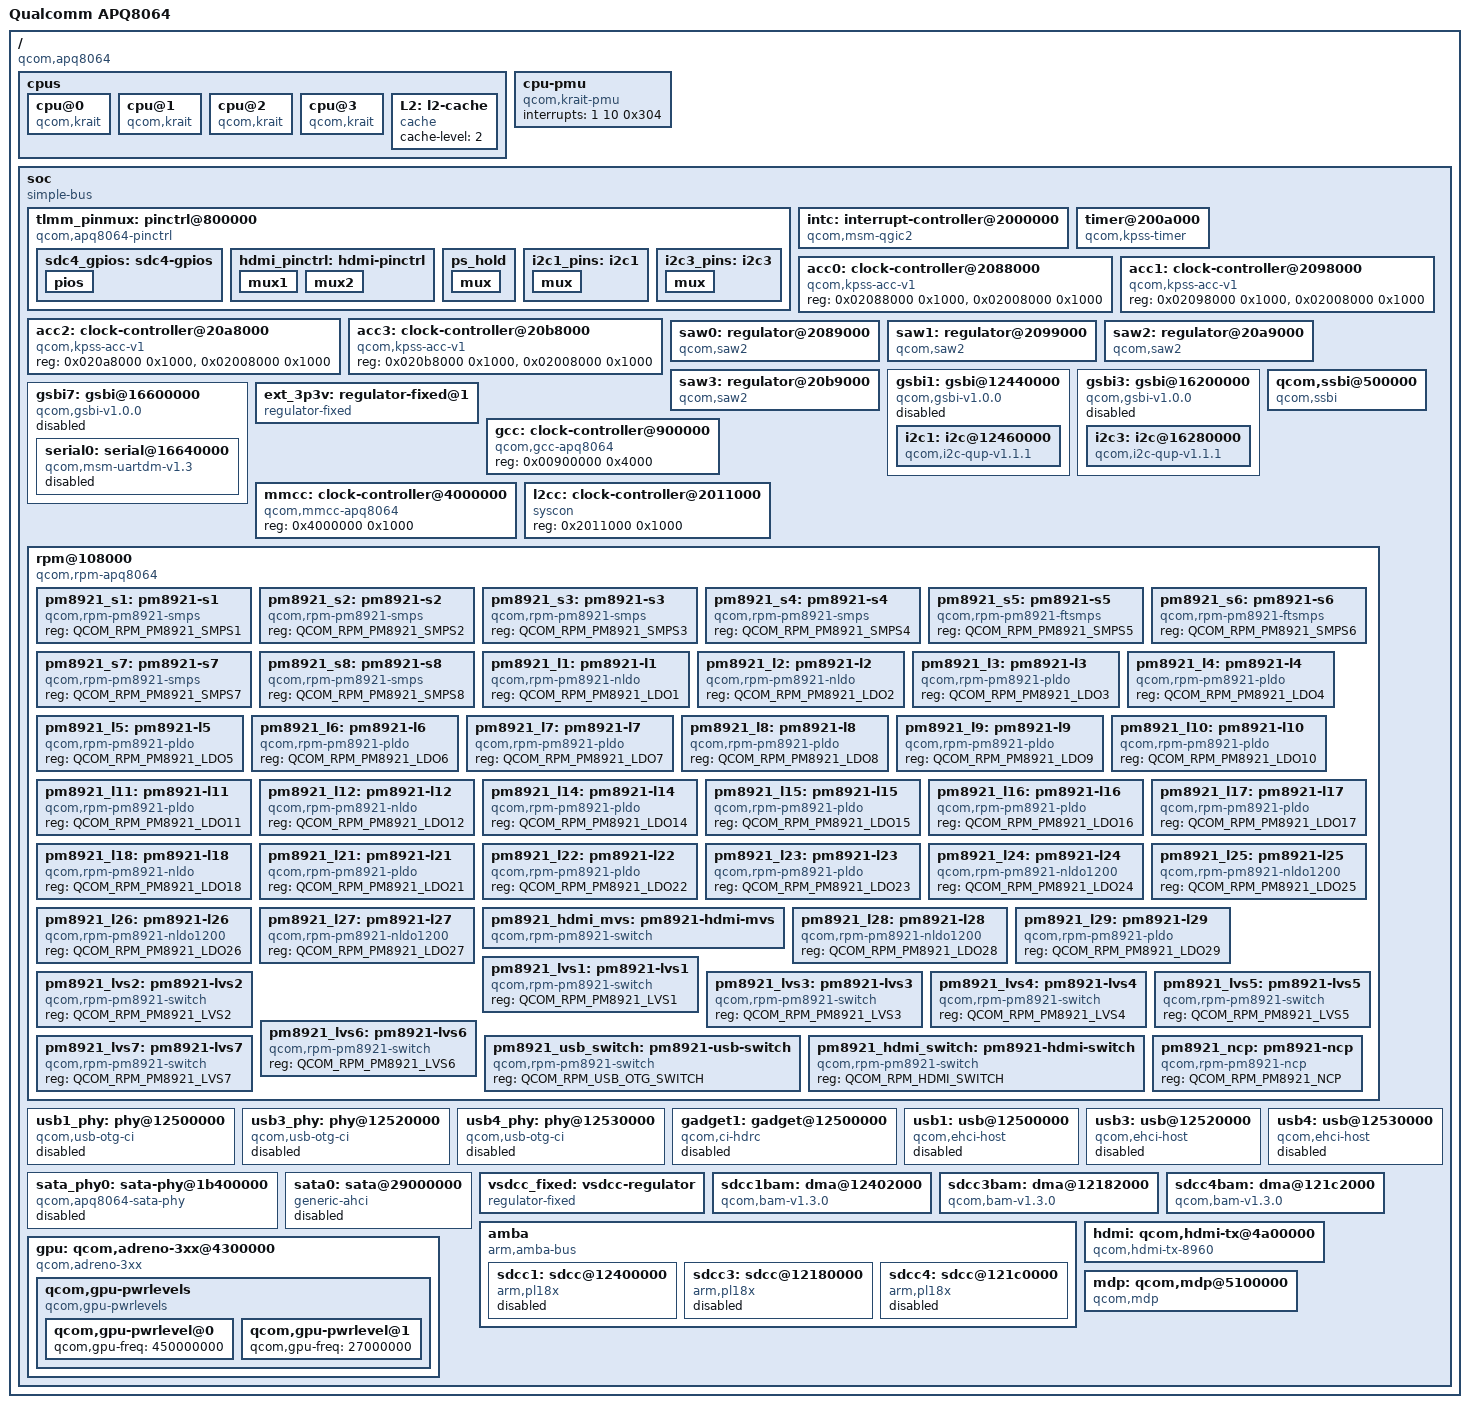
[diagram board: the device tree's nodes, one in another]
/dts-v1/;

#include "skeleton.dtsi"
#include <dt-bindings/gpio/gpio.h>
#include <dt-bindings/clock/qcom,gcc-msm8960.h>
#include <dt-bindings/reset/qcom,gcc-msm8960.h>
#include <dt-bindings/clock/qcom,mmcc-msm8960.h>
#include <dt-bindings/mfd/qcom-rpm.h>
#include <dt-bindings/soc/qcom,gsbi.h>
#include <dt-bindings/interrupt-controller/arm-gic.h>

/ {
	model = "Qualcomm APQ8064";
	compatible = "qcom,apq8064";
	interrupt-parent = <&intc>;

	cpus {
		#address-cells = <1>;
		#size-cells = <0>;

		cpu@0 {
			compatible = "qcom,krait";
			enable-method = "qcom,kpss-acc-v1";
			device_type = "cpu";
			reg = <0>;
			next-level-cache = <&L2>;
			qcom,acc = <&acc0>;
			qcom,saw = <&saw0>;
		};

		cpu@1 {
			compatible = "qcom,krait";
			enable-method = "qcom,kpss-acc-v1";
			device_type = "cpu";
			reg = <1>;
			next-level-cache = <&L2>;
			qcom,acc = <&acc1>;
			qcom,saw = <&saw1>;
		};

		cpu@2 {
			compatible = "qcom,krait";
			enable-method = "qcom,kpss-acc-v1";
			device_type = "cpu";
			reg = <2>;
			next-level-cache = <&L2>;
			qcom,acc = <&acc2>;
			qcom,saw = <&saw2>;
		};

		cpu@3 {
			compatible = "qcom,krait";
			enable-method = "qcom,kpss-acc-v1";
			device_type = "cpu";
			reg = <3>;
			next-level-cache = <&L2>;
			qcom,acc = <&acc3>;
			qcom,saw = <&saw3>;
		};

		L2: l2-cache {
			compatible = "cache";
			cache-level = <2>;
		};
	};

	cpu-pmu {
		compatible = "qcom,krait-pmu";
		interrupts = <1 10 0x304>;
	};

	soc: soc {
		#address-cells = <1>;
		#size-cells = <1>;
		ranges;
		compatible = "simple-bus";

		tlmm_pinmux: pinctrl@800000 {
			compatible = "qcom,apq8064-pinctrl";
			reg = <0x800000 0x4000>;

			gpio-controller;
			#gpio-cells = <2>;
			interrupt-controller;
			#interrupt-cells = <2>;
			interrupts = <0 16 IRQ_TYPE_LEVEL_HIGH>;

			pinctrl-names = "default";
			pinctrl-0 = <&ps_hold>;

			sdc4_gpios: sdc4-gpios {
				pios {
					pins = "gpio63", "gpio64", "gpio65", "gpio66", "gpio67", "gpio68";
					function = "sdc4";
				};
			};

			hdmi_pinctrl: hdmi-pinctrl {
				mux1 {
					pins = "gpio69", "gpio70", "gpio71";
					function = "hdmi";
					bias-pull-up;
					drive-strength = <2>;
				};
				mux2 {
					pins = "gpio72";
					function = "hdmi";
					bias-pull-down;
					drive-strength = <16>;
				};
			};
			ps_hold: ps_hold {
				mux {
					pins = "gpio78";
					function = "ps_hold";
				};
			};

			i2c1_pins: i2c1 {
				mux {
					pins = "gpio20", "gpio21";
					function = "gsbi1";
				};
			};

			i2c3_pins: i2c3 {
				mux {
					pins = "gpio8", "gpio9";
					function = "gsbi3";
				};
			};
		};

		intc: interrupt-controller@2000000 {
			compatible = "qcom,msm-qgic2";
			interrupt-controller;
			#interrupt-cells = <3>;
			reg = <0x02000000 0x1000>,
			      <0x02002000 0x1000>;
		};

		timer@200a000 {
			compatible = "qcom,kpss-timer", "qcom,msm-timer";
			interrupts = <1 1 0x301>,
				     <1 2 0x301>,
				     <1 3 0x301>;
			reg = <0x0200a000 0x100>;
			clock-frequency = <27000000>,
					  <32768>;
			cpu-offset = <0x80000>;
		};

		acc0: clock-controller@2088000 {
			compatible = "qcom,kpss-acc-v1";
			reg = <0x02088000 0x1000>, <0x02008000 0x1000>;
		};

		acc1: clock-controller@2098000 {
			compatible = "qcom,kpss-acc-v1";
			reg = <0x02098000 0x1000>, <0x02008000 0x1000>;
		};

		acc2: clock-controller@20a8000 {
			compatible = "qcom,kpss-acc-v1";
			reg = <0x020a8000 0x1000>, <0x02008000 0x1000>;
		};

		acc3: clock-controller@20b8000 {
			compatible = "qcom,kpss-acc-v1";
			reg = <0x020b8000 0x1000>, <0x02008000 0x1000>;
		};

		saw0: regulator@2089000 {
			compatible = "qcom,saw2";
			reg = <0x02089000 0x1000>, <0x02009000 0x1000>;
			regulator;
		};

		saw1: regulator@2099000 {
			compatible = "qcom,saw2";
			reg = <0x02099000 0x1000>, <0x02009000 0x1000>;
			regulator;
		};

		saw2: regulator@20a9000 {
			compatible = "qcom,saw2";
			reg = <0x020a9000 0x1000>, <0x02009000 0x1000>;
			regulator;
		};

		saw3: regulator@20b9000 {
			compatible = "qcom,saw2";
			reg = <0x020b9000 0x1000>, <0x02009000 0x1000>;
			regulator;
		};

		gsbi1: gsbi@12440000 {
			status = "disabled";
			compatible = "qcom,gsbi-v1.0.0";
			reg = <0x12440000 0x100>;
			clocks = <&gcc GSBI1_H_CLK>;
			clock-names = "iface";
			#address-cells = <1>;
			#size-cells = <1>;
			ranges;

			i2c1: i2c@12460000 {
				compatible = "qcom,i2c-qup-v1.1.1";
				reg = <0x12460000 0x1000>;
				interrupts = <0 194 IRQ_TYPE_NONE>;
				clocks = <&gcc GSBI1_QUP_CLK>, <&gcc GSBI1_H_CLK>;
				clock-names = "core", "iface";
				#address-cells = <1>;
				#size-cells = <0>;
			};
		};

		gsbi3: gsbi@16200000 {
			status = "disabled";
			compatible = "qcom,gsbi-v1.0.0";
			reg = <0x16200000 0x100>;
			clocks = <&gcc GSBI3_H_CLK>;
			clock-names = "iface";
			#address-cells = <1>;
			#size-cells = <1>;
			ranges;

			i2c3: i2c@16280000 {
				compatible = "qcom,i2c-qup-v1.1.1";
				reg = <0x16280000 0x1000>;
				interrupts = <0 151 IRQ_TYPE_NONE>;
				clocks = <&gcc GSBI3_QUP_CLK>, <&gcc GSBI3_H_CLK>;
				clock-names = "core", "iface";
			};
		};

		gsbi7: gsbi@16600000 {
			status = "disabled";
			compatible = "qcom,gsbi-v1.0.0";
			reg = <0x16600000 0x100>;
			clocks = <&gcc GSBI7_H_CLK>;
			clock-names = "iface";
			#address-cells = <1>;
			#size-cells = <1>;
			ranges;

			serial0: serial@16640000 {
				compatible = "qcom,msm-uartdm-v1.3", "qcom,msm-uartdm";
				reg = <0x16640000 0x1000>,
				      <0x16600000 0x1000>;
				interrupts = <0 158 0x0>;
				clocks = <&gcc GSBI7_UART_CLK>, <&gcc GSBI7_H_CLK>;
				clock-names = "core", "iface";
				status = "disabled";
			};
		};

		ext_3p3v: regulator-fixed@1 {
			compatible = "regulator-fixed";
			regulator-min-microvolt = <3300000>;
			regulator-max-microvolt = <3300000>;
			regulator-name = "ext_3p3v";
			regulator-type = "voltage";
			startup-delay-us = <0>;
			gpio = <&tlmm_pinmux 77 GPIO_ACTIVE_HIGH>;
			enable-active-high;
			regulator-boot-on;
		};

		qcom,ssbi@500000 {
			compatible = "qcom,ssbi";
			reg = <0x00500000 0x1000>;
			qcom,controller-type = "pmic-arbiter";
		};

		gcc: clock-controller@900000 {
			compatible = "qcom,gcc-apq8064";
			reg = <0x00900000 0x4000>;
			#clock-cells = <1>;
			#reset-cells = <1>;
		};

		mmcc: clock-controller@4000000 {
			compatible = "qcom,mmcc-apq8064";
			reg = <0x4000000 0x1000>;
			#clock-cells = <1>;
			#reset-cells = <1>;
		};

		l2cc: clock-controller@2011000 {
			compatible	= "syscon";
			reg		= <0x2011000 0x1000>;
		};

		rpm@108000 {
			compatible	= "qcom,rpm-apq8064";
			reg		= <0x108000 0x1000>;
			qcom,ipc	= <&l2cc 0x8 2>;

			interrupts	= <0 19 0>, <0 21 0>, <0 22 0>;
			interrupt-names	= "ack", "err", "wakeup";

			#address-cells	= <1>;
			#size-cells	= <0>;

			/* Buck SMPS */
			pm8921_s1: pm8921-s1 {
				compatible	= "qcom,rpm-pm8921-smps";
				reg		= <QCOM_RPM_PM8921_SMPS1>;
			};

			pm8921_s2: pm8921-s2 {
				compatible	= "qcom,rpm-pm8921-smps";
				reg		= <QCOM_RPM_PM8921_SMPS2>;
			};

			pm8921_s3: pm8921-s3 {
				compatible	= "qcom,rpm-pm8921-smps";
				reg		= <QCOM_RPM_PM8921_SMPS3>;
			};

			pm8921_s4: pm8921-s4 {
				compatible	= "qcom,rpm-pm8921-smps";
				reg		= <QCOM_RPM_PM8921_SMPS4>;
			};

			pm8921_s5: pm8921-s5 {
				compatible	= "qcom,rpm-pm8921-ftsmps";
				reg		= <QCOM_RPM_PM8921_SMPS5>;
			};

			pm8921_s6: pm8921-s6 {
				compatible	= "qcom,rpm-pm8921-ftsmps";
				reg		= <QCOM_RPM_PM8921_SMPS6>;
			};

			pm8921_s7: pm8921-s7 {
				compatible	= "qcom,rpm-pm8921-smps";
				reg		= <QCOM_RPM_PM8921_SMPS7>;
			};

			pm8921_s8: pm8921-s8 {
				compatible	= "qcom,rpm-pm8921-smps";
				reg		= <QCOM_RPM_PM8921_SMPS8>;
			};

			/* PMOS LDO */
			pm8921_l1: pm8921-l1 {
				compatible	= "qcom,rpm-pm8921-nldo";
				reg		= <QCOM_RPM_PM8921_LDO1>;
			};

			pm8921_l2: pm8921-l2 {
				compatible	= "qcom,rpm-pm8921-nldo";
				reg		= <QCOM_RPM_PM8921_LDO2>;
			};

			pm8921_l3: pm8921-l3 {
				compatible	= "qcom,rpm-pm8921-pldo";
				reg		= <QCOM_RPM_PM8921_LDO3>;
			};

			pm8921_l4: pm8921-l4 {
				compatible	= "qcom,rpm-pm8921-pldo";
				reg		= <QCOM_RPM_PM8921_LDO4>;
			};

			pm8921_l5: pm8921-l5 {
				compatible	= "qcom,rpm-pm8921-pldo";
				reg		= <QCOM_RPM_PM8921_LDO5>;
			};

			pm8921_l6: pm8921-l6 {
				compatible	= "qcom,rpm-pm8921-pldo";
				reg		= <QCOM_RPM_PM8921_LDO6>;
			};

			pm8921_l7: pm8921-l7 {
				compatible	= "qcom,rpm-pm8921-pldo";
				reg		= <QCOM_RPM_PM8921_LDO7>;
			};

			pm8921_l8: pm8921-l8 {
				compatible	= "qcom,rpm-pm8921-pldo";
				reg		= <QCOM_RPM_PM8921_LDO8>;
			};

			pm8921_l9: pm8921-l9 {
				compatible	= "qcom,rpm-pm8921-pldo";
				reg		= <QCOM_RPM_PM8921_LDO9>;
			};

			pm8921_l10: pm8921-l10 {
				compatible	= "qcom,rpm-pm8921-pldo";
				reg		= <QCOM_RPM_PM8921_LDO10>;
			};

			pm8921_l11: pm8921-l11 {
				compatible	= "qcom,rpm-pm8921-pldo";
				reg		= <QCOM_RPM_PM8921_LDO11>;
			};

			pm8921_l12: pm8921-l12 {
				compatible	= "qcom,rpm-pm8921-nldo";
				reg		= <QCOM_RPM_PM8921_LDO12>;
			};

			pm8921_l14: pm8921-l14 {
				compatible	= "qcom,rpm-pm8921-pldo";
				reg		= <QCOM_RPM_PM8921_LDO14>;
			};

			pm8921_l15: pm8921-l15 {
				compatible	= "qcom,rpm-pm8921-pldo";
				reg		= <QCOM_RPM_PM8921_LDO15>;
			};

			pm8921_l16: pm8921-l16 {
				compatible	= "qcom,rpm-pm8921-pldo";
				reg		= <QCOM_RPM_PM8921_LDO16>;
			};

			pm8921_l17: pm8921-l17 {
				compatible	= "qcom,rpm-pm8921-pldo";
				reg		= <QCOM_RPM_PM8921_LDO17>;
			};

			pm8921_l18: pm8921-l18 {
				compatible	= "qcom,rpm-pm8921-nldo";
				reg		= <QCOM_RPM_PM8921_LDO18>;
			};

			pm8921_l21: pm8921-l21 {
				compatible	= "qcom,rpm-pm8921-pldo";
				reg		= <QCOM_RPM_PM8921_LDO21>;
			};

			pm8921_l22: pm8921-l22 {
				compatible	= "qcom,rpm-pm8921-pldo";
				reg		= <QCOM_RPM_PM8921_LDO22>;
			};

			pm8921_l23: pm8921-l23 {
				compatible	= "qcom,rpm-pm8921-pldo";
				reg		= <QCOM_RPM_PM8921_LDO23>;
			};

			pm8921_l24: pm8921-l24 {
				compatible	= "qcom,rpm-pm8921-nldo1200";
				reg		= <QCOM_RPM_PM8921_LDO24>;
			};

			pm8921_l25: pm8921-l25 {
				compatible	= "qcom,rpm-pm8921-nldo1200";
				reg		= <QCOM_RPM_PM8921_LDO25>;
			};

			pm8921_l26: pm8921-l26 {
				compatible	= "qcom,rpm-pm8921-nldo1200";
				reg		= <QCOM_RPM_PM8921_LDO26>;
			};

			pm8921_l27: pm8921-l27 {
				compatible	= "qcom,rpm-pm8921-nldo1200";
				reg		= <QCOM_RPM_PM8921_LDO27>;
			};

			pm8921_hdmi_mvs: pm8921-hdmi-mvs {
				compatible	= "qcom,rpm-pm8921-switch";
				reg		= <QCOM_RPM_HDMI_SWITCH>;
				regulator-always-on;
				bias-pull-down;
			};

			pm8921_l28: pm8921-l28 {
				compatible	= "qcom,rpm-pm8921-nldo1200";
				reg		= <QCOM_RPM_PM8921_LDO28>;
			};

			pm8921_l29: pm8921-l29 {
				compatible	= "qcom,rpm-pm8921-pldo";
				reg		= <QCOM_RPM_PM8921_LDO29>;
			};

			/* Low Voltage Switch */
			pm8921_lvs1: pm8921-lvs1 {
				compatible	= "qcom,rpm-pm8921-switch";
				reg		= <QCOM_RPM_PM8921_LVS1>;
			};

			pm8921_lvs2: pm8921-lvs2 {
				compatible	= "qcom,rpm-pm8921-switch";
				reg		= <QCOM_RPM_PM8921_LVS2>;
			};

			pm8921_lvs3: pm8921-lvs3 {
				compatible	= "qcom,rpm-pm8921-switch";
				reg		= <QCOM_RPM_PM8921_LVS3>;
			};

			pm8921_lvs4: pm8921-lvs4 {
				compatible	= "qcom,rpm-pm8921-switch";
				reg		= <QCOM_RPM_PM8921_LVS4>;
			};

			pm8921_lvs5: pm8921-lvs5 {
				compatible	= "qcom,rpm-pm8921-switch";
				reg		= <QCOM_RPM_PM8921_LVS5>;
			};

			pm8921_lvs6: pm8921-lvs6 {
				compatible	= "qcom,rpm-pm8921-switch";
				reg		= <QCOM_RPM_PM8921_LVS6>;
			};

			pm8921_lvs7: pm8921-lvs7 {
				compatible	= "qcom,rpm-pm8921-switch";
				reg		= <QCOM_RPM_PM8921_LVS7>;
			};

			pm8921_usb_switch: pm8921-usb-switch {
				compatible	= "qcom,rpm-pm8921-switch";
				reg		= <QCOM_RPM_USB_OTG_SWITCH>;
			};

			pm8921_hdmi_switch: pm8921-hdmi-switch {
				compatible	= "qcom,rpm-pm8921-switch";
				reg		= <QCOM_RPM_HDMI_SWITCH>;
			};

			pm8921_ncp: pm8921-ncp {
				compatible	= "qcom,rpm-pm8921-ncp";
				reg		= <QCOM_RPM_PM8921_NCP>;
			};
		};

		usb1_phy: phy@12500000 {
			compatible	= "qcom,usb-otg-ci";
			reg		= <0x12500000 0x400>;
			interrupts	= <0 100 IRQ_TYPE_NONE>;
			status		= "disabled";
			dr_mode		= "host";

			clocks		= <&gcc USB_HS1_XCVR_CLK>,
					  <&gcc USB_HS1_H_CLK>;
			clock-names	= "core", "iface";

			resets		= <&gcc USB_HS1_RESET>;
			reset-names	= "link";
		};

		usb3_phy: phy@12520000 {
			compatible	= "qcom,usb-otg-ci";
			reg		= <0x12520000 0x400>;
			interrupts	= <0 188 IRQ_TYPE_NONE>;
			status		= "disabled";
			dr_mode		= "host";

			clocks		= <&gcc USB_HS3_XCVR_CLK>,
					  <&gcc USB_HS3_H_CLK>;
			clock-names	= "core", "iface";

			resets		= <&gcc USB_HS3_RESET>;
			reset-names	= "link";
		};

		usb4_phy: phy@12530000 {
			compatible	= "qcom,usb-otg-ci";
			reg		= <0x12530000 0x400>;
			interrupts	= <0 215 IRQ_TYPE_NONE>;
			status		= "disabled";
			dr_mode		= "host";

			clocks		= <&gcc USB_HS4_XCVR_CLK>,
					  <&gcc USB_HS4_H_CLK>;
			clock-names	= "core", "iface";

			resets		= <&gcc USB_HS4_RESET>;
			reset-names	= "link";
		};

		gadget1: gadget@12500000 {
			compatible	= "qcom,ci-hdrc";
			reg		= <0x12500000 0x400>;
			status		= "disabled";
			dr_mode		= "peripheral";
			interrupts	= <0 100 IRQ_TYPE_NONE>;
			usb-phy		= <&usb1_phy>;
		};

		usb1: usb@12500000 {
			compatible	= "qcom,ehci-host";
			reg		= <0x12500000 0x400>;
			interrupts	= <0 100 IRQ_TYPE_NONE>;
			status		= "disabled";
			usb-phy		= <&usb1_phy>;
		};

		usb3: usb@12520000 {
			compatible	= "qcom,ehci-host";
			reg		= <0x12520000 0x400>;
			interrupts	= <0 188 IRQ_TYPE_NONE>;
			status		= "disabled";
			usb-phy		= <&usb3_phy>;
		};

		usb4: usb@12530000 {
			compatible	= "qcom,ehci-host";
			reg		= <0x12530000 0x400>;
			interrupts	= <0 215 IRQ_TYPE_NONE>;
			status		= "disabled";
			usb-phy		= <&usb4_phy>;
		};

		sata_phy0: sata-phy@1b400000{
			compatible	= "qcom,apq8064-sata-phy";
			status		= "disabled";
			reg		= <0x1b400000 0x200>;
			reg-names	= "phy_mem";
			clocks		= <&gcc SATA_PHY_CFG_CLK>;
			clock-names	= "cfg";
			#phy-cells	= <0>;
		};

		sata0: sata@29000000 {
			compatible		= "generic-ahci";
			status			= "disabled";
			reg			= <0x29000000 0x180>;
			interrupts		= <0 209 0>;

			clocks			= <&gcc SFAB_SATA_S_H_CLK>,
						<&gcc SATA_H_CLK>,
						<&gcc SATA_A_CLK>,
						<&gcc SATA_RXOOB_CLK>,
						<&gcc SATA_PMALIVE_CLK>;
			clock-names		= "slave_iface",
						"iface",
						"bus",
						"rxoob",
						"core_pmalive";

			assigned-clocks		= <&gcc SATA_RXOOB_CLK>,
						<&gcc SATA_PMALIVE_CLK>;
			assigned-clock-rates	= <100000000>, <100000000>;

			phys			= <&sata_phy0>;
			phy-names		= "sata-phy";
		};

		/* Temporary fixed regulator */
		vsdcc_fixed: vsdcc-regulator {
			compatible = "regulator-fixed";
			regulator-name = "SDCC Power";
			regulator-min-microvolt = <2700000>;
			regulator-max-microvolt = <2700000>;
			regulator-always-on;
		};

		sdcc1bam:dma@12402000{
			compatible = "qcom,bam-v1.3.0";
			reg = <0x12402000 0x8000>;
			interrupts = <0 98 0>;
			clocks = <&gcc SDC1_H_CLK>;
			clock-names = "bam_clk";
			#dma-cells = <1>;
			qcom,ee = <0>;
		};

		sdcc3bam:dma@12182000{
			compatible = "qcom,bam-v1.3.0";
			reg = <0x12182000 0x8000>;
			interrupts = <0 96 0>;
			clocks = <&gcc SDC3_H_CLK>;
			clock-names = "bam_clk";
			#dma-cells = <1>;
			qcom,ee = <0>;
		};

		sdcc4bam:dma@121c2000{
			compatible = "qcom,bam-v1.3.0";
			reg = <0x121c2000 0x8000>;
			interrupts = <0 95 0>;
			clocks = <&gcc SDC4_H_CLK>;
			clock-names = "bam_clk";
			#dma-cells = <1>;
			qcom,ee = <0>;
		};

		amba {
			compatible = "arm,amba-bus";
			#address-cells = <1>;
			#size-cells = <1>;
			ranges;
			sdcc1: sdcc@12400000 {
				status		= "disabled";
				compatible	= "arm,pl18x", "arm,primecell";
				arm,primecell-periphid = <0x00051180>;
				reg		= <0x12400000 0x2000>;
				interrupts	= <GIC_SPI 104 IRQ_TYPE_LEVEL_HIGH>;
				interrupt-names	= "cmd_irq";
				clocks		= <&gcc SDC1_CLK>, <&gcc SDC1_H_CLK>;
				clock-names	= "mclk", "apb_pclk";
				bus-width	= <8>;
				max-frequency	= <96000000>;
				non-removable;
				cap-sd-highspeed;
				cap-mmc-highspeed;
				vmmc-supply = <&vsdcc_fixed>;
				dmas = <&sdcc1bam 2>, <&sdcc1bam 1>;
				dma-names = "tx", "rx";
			};

			sdcc3: sdcc@12180000 {
				compatible	= "arm,pl18x", "arm,primecell";
				arm,primecell-periphid = <0x00051180>;
				status		= "disabled";
				reg		= <0x12180000 0x2000>;
				interrupts	= <GIC_SPI 102 IRQ_TYPE_LEVEL_HIGH>;
				interrupt-names	= "cmd_irq";
				clocks		= <&gcc SDC3_CLK>, <&gcc SDC3_H_CLK>;
				clock-names	= "mclk", "apb_pclk";
				bus-width	= <4>;
				cap-sd-highspeed;
				cap-mmc-highspeed;
				max-frequency	= <192000000>;
				no-1-8-v;
				vmmc-supply = <&vsdcc_fixed>;
				dmas = <&sdcc3bam 2>, <&sdcc3bam 1>;
				dma-names = "tx", "rx";
			};

			sdcc4: sdcc@121c0000 {
				compatible	= "arm,pl18x", "arm,primecell";
				arm,primecell-periphid = <0x00051180>;
				status		= "disabled";
				reg		= <0x121c0000 0x2000>;
				interrupts	= <GIC_SPI 101 IRQ_TYPE_LEVEL_HIGH>;
				interrupt-names	= "cmd_irq";
				clocks		= <&gcc SDC4_CLK>, <&gcc SDC4_H_CLK>;
				clock-names	= "mclk", "apb_pclk";
				bus-width	= <4>;
				cap-sd-highspeed;
				cap-mmc-highspeed;
				max-frequency	= <48000000>;
				vmmc-supply = <&vsdcc_fixed>;
				vqmmc-supply = <&vsdcc_fixed>;
				dmas = <&sdcc4bam 2>, <&sdcc4bam 1>;
				dma-names = "tx", "rx";
				pinctrl-names = "default";
				pinctrl-0 = <&sdc4_gpios>;
			};
		};

		hdmi: qcom,hdmi-tx@4a00000 {
			compatible = "qcom,hdmi-tx-8960";
			reg-names = "core_physical";
			reg = <0x04a00000 0x1000>;
			interrupts = <GIC_SPI 79 0>;
			clock-names =
			    "core_clk",
			    "master_iface_clk",
			    "slave_iface_clk";
			clocks =
			    <&mmcc HDMI_APP_CLK>,
			    <&mmcc HDMI_M_AHB_CLK>,
			    <&mmcc HDMI_S_AHB_CLK>;
			qcom,hdmi-tx-ddc-clk = <&tlmm_pinmux 70
						GPIO_ACTIVE_HIGH>;
			qcom,hdmi-tx-ddc-data = <&tlmm_pinmux 71
						GPIO_ACTIVE_HIGH>;
			qcom,hdmi-tx-hpd = <&tlmm_pinmux 72
						GPIO_ACTIVE_HIGH>;
			core-vdda-supply = <&pm8921_hdmi_mvs>;
			hdmi-mux-supply = <&ext_3p3v>;
			pinctrl-names = "default";
			pinctrl-0 = <&hdmi_pinctrl>;
		};

		gpu: qcom,adreno-3xx@4300000 {
			compatible = "qcom,adreno-3xx";
			reg = <0x04300000 0x20000>;
			reg-names = "kgsl_3d0_reg_memory";
			interrupts = <GIC_SPI 80 0>;
			interrupt-names = "kgsl_3d0_irq";
			clock-names =
			    "core_clk",
			    "iface_clk",
			    "mem_clk",
			    "mem_iface_clk";
			clocks =
			    <&mmcc GFX3D_CLK>,
			    <&mmcc GFX3D_AHB_CLK>,
			    <&mmcc GFX3D_AXI_CLK>,
			    <&mmcc MMSS_IMEM_AHB_CLK>;
			qcom,chipid = <0x03020002>;
			qcom,gpu-pwrlevels {
				compatible = "qcom,gpu-pwrlevels";
				qcom,gpu-pwrlevel@0 {
					qcom,gpu-freq = <450000000>;
				};
				qcom,gpu-pwrlevel@1 {
					qcom,gpu-freq = <27000000>;
				};
			};
		};

		mdp: qcom,mdp@5100000 {
			compatible = "qcom,mdp";
			reg = <0x05100000 0xf0000>;
			interrupts = <GIC_SPI 75 0>;
			connectors = <&hdmi>;
			gpus = <&gpu>;
			clock-names =
			    "core_clk",
			    "iface_clk",
			    "lut_clk",
			    "src_clk",
			    "hdmi_clk",
			    "mdp_clk",
			    "mdp_axi_clk";
			clocks =
			    <&mmcc MDP_CLK>,
			    <&mmcc MDP_AHB_CLK>,
			    <&mmcc MDP_LUT_CLK>,
			    <&mmcc TV_SRC>,
			    <&mmcc HDMI_TV_CLK>,
			    <&mmcc MDP_TV_CLK>,
			    <&mmcc MDP_AXI_CLK>;
//			vdd-supply = <&footswitch_mdp>;
		};
	};
};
